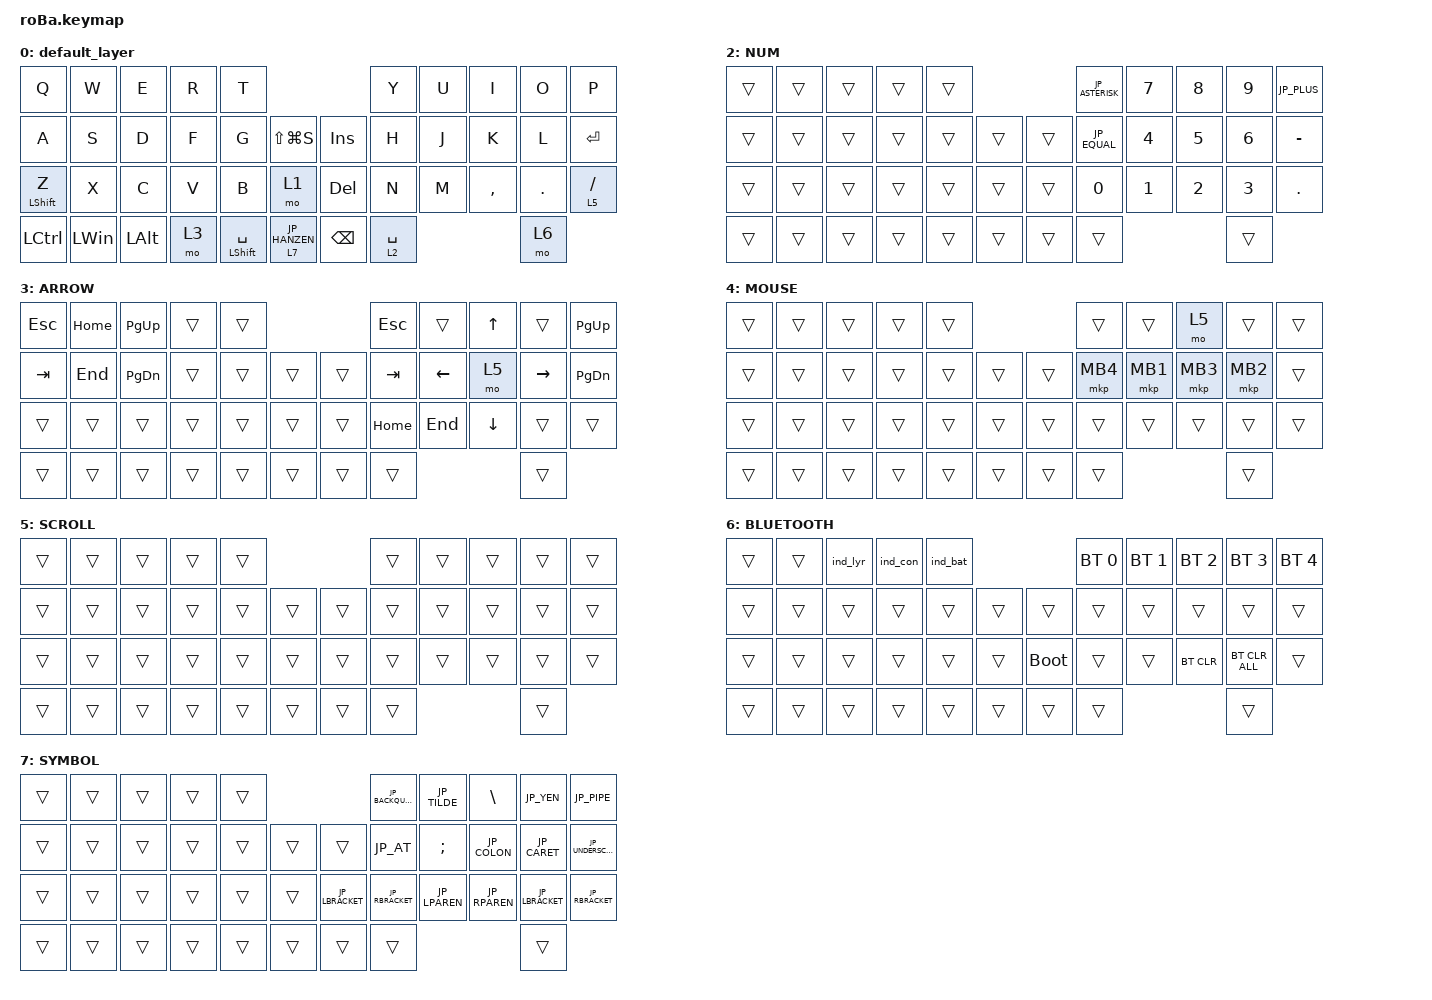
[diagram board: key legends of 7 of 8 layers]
#include <behaviors.dtsi>
#include <dt-bindings/zmk/bt.h>
#include <dt-bindings/zmk/keys.h>
#include <dt-bindings/zmk/pointing.h>
#include <behaviors/rgbled_widget.dtsi>  // led

//エンコーダのスクロール量を定義
#define ZMK_POINTING_DEFAULT_SCRL_VAL 80

// OS設定を日本語キーボードのまま使用するための変換定義
#define JP_DQUOTE       AT                // "
#define JP_AMPERSAND    CARET             // &
#define JP_QUOTE        AMPERSAND         // '
#define JP_EQUAL        UNDER             // =
#define JP_CARET        EQUAL             // ^
#define JP_YEN          0x89              // ¥
#define JP_PLUS         COLON             // +
#define JP_TILDE        PLUS              // ~
#define JP_PIPE         LS(0x89)          // |
#define JP_AT           LEFT_BRACKET      // @
#define JP_COLON        SINGLE_QUOTE      // :
#define JP_ASTERISK     DOUBLE_QUOTES     // *
#define JP_BACKQUOTE    LEFT_BRACE        // `
#define JP_UNDERSCORE   LS(0x87)          // _
#define JP_LBRACKET     RIGHT_BRACKET     // [
#define JP_RBRACKET     BACKSLASH         // ]
#define JP_LPAREN       ASTERISK          // (
#define JP_RPAREN       LEFT_PARENTHESIS  // )
#define JP_LBRACE       RIGHT_BRACE       // {
#define JP_RBRACE       PIPE              // }
#define JP_KANA         LANGUAGE_1        // かな
#define JP_EISU         LANGUAGE_2        // 英数
#define JP_HANZEN       GRAVE             // 半角/全角

&mt {
    flavor = "balanced";
    quick-tap-ms = <0>;
};

&trackball {
    automouse-layer = <4>;
    scroll-layers = <5>;

    // arrows {
    //     layers = <3>;
    //     bindings =
    //         <&kp RIGHT_ARROW>,
    //         <&kp LEFT_ARROW>,
    //         <&kp UP_ARROW>,
    //         <&kp DOWN_ARROW>;
    //     tick = <10>;
    //     wait-ms = <5>;
    //     tap-ms = <5>;
    // };
};

/ {
    combos {
        compatible = "zmk,combos";

        tab {
            bindings = <&kp TAB>;
            key-positions = <11 12>;
        };

        shift_tab {
            bindings = <&kp LS(TAB)>;
            key-positions = <12 13>;
        };

//        muhennkann {
//            bindings = <&to_layer_0 INT_MUHENKAN>;
//            key-positions = <11 10>;
//        };
//
        double_quotation {
            bindings = <&kp MINUS>;
            key-positions = <18 19>;
        };

        eq {
            bindings = <&kp EQUAL>;
            key-positions = <24 25>;
        };
    };

    macros {
        to_layer_0: to_layer_0 {
            compatible = "zmk,behavior-macro-one-param";
            #binding-cells = <1>;
            bindings = <&to 0 &macro_param_1to1 &kp MACRO_PLACEHOLDER>;
            label = "TO_LAYER_0";
        };

    };

    behaviors {
        // スクロール方向を逆にしたい場合は <&msc SCRL_DOWN> と <&msc SCRL_UP> を入れ替えてください
        encoder_msc_down_up: encoder_msc_down_up {
            compatible = "zmk,behavior-sensor-rotate";
            label = "ENCODER_MSC_DOWN_UP";
            #sensor-binding-cells = <0>;
            bindings = <&msc SCRL_DOWN>, <&msc SCRL_UP>;

            tap-ms = <20>;
        };

        lt_to_layer_0: lt_to_layer_0 {
            compatible = "zmk,behavior-hold-tap";
            label = "LAYER_TAP_TO_0";
            bindings = <&mo>, <&to_layer_0>;

            #binding-cells = <2>;
            tapping-term-ms = <200>;
        };

    };

    keymap {
        compatible = "zmk,keymap";

        default_layer {
            bindings = <
&kp Q  &kp W         &kp E         &kp R      &kp T                                                            &kp Y          &kp U  &kp I    &kp O    &kp P
&kp A  &kp S  &kp D  &kp F  &kp G  &kp LS(LG(S))   &kp INS  &kp H  &kp J  &kp K  &kp  L  &kp ENTER
&mt LEFT_SHIFT Z  &kp X         &kp C         &kp V      &kp B                 &mo 1              &kp DEL                 &kp N          &kp M  &kp COMMA  &kp DOT  &lt_to_layer_0 5 SLASH
&kp LCTRL  &kp LEFT_WIN  &kp LEFT_ALT  &mo 3   &mt LEFT_SHIFT SPACE  &lt_to_layer_0 7 JP_HANZEN  &kp BACKSPACE  &lt 2 SPACE  &mo 6  
            >;

            sensor-bindings = <&encoder_msc_down_up>;

            //sensor-bindings = <&inc_dec_kp K_SCROLL_DOWN K_SCROLL_UP>;
        };

        FUNCTION {
            bindings = <
&trans  &trans  &trans  &trans  &trans                      &kp F1  &kp F2  &kp F3  &kp F4  &kp F5
&trans  &trans  &trans  &trans  &trans              &trans  &kp F6  &kp F7  &kp F8  &kp F9   &kp F10
&trans  &trans  &trans  &trans  &trans  &trans      &trans  &trans  &trans  &trans  &kp F11  &kp F12
&trans  &trans  &trans  &trans  &trans  &trans      &trans  &trans                           &trans
            >;
        };

        NUM {
            bindings = <
&trans  &trans  &trans  &trans  &trans                      &kp JP_ASTERISK  &kp N7  &kp N8  &kp N9  &kp JP_PLUS  
&trans  &trans  &trans  &trans  &trans  &trans      &trans  &kp JP_EQUAL     &kp N4  &kp N5  &kp N6  &kp MINUS
&trans  &trans  &trans  &trans  &trans  &trans      &trans  &kp N0           &kp N1  &kp N2  &kp N3  &kp DOT
&trans  &trans  &trans  &trans  &trans  &trans      &trans  &trans                          &trans
            >;
        };

        ARROW {
            bindings = <
&kp ESCAPE  &kp HOME  &kp PAGE_UP    &trans  &trans                      &kp ESCAPE  &trans          &kp UP_ARROW    &trans           &kp PAGE_UP
&kp TAB     &kp END   &kp PAGE_DOWN  &trans  &trans  &trans      &trans  &kp TAB  &kp LEFT_ARROW  &mo  5 &kp RIGHT_ARROW  &kp PAGE_DOWN
&trans      &trans    &trans         &trans  &trans  &trans      &trans  &kp HOME  &kp END          &kp DOWN_ARROW          &trans           &trans
&trans      &trans    &trans         &trans  &trans  &trans      &trans  &trans                                                   &trans
            >;

            sensor-bindings = <&inc_dec_kp LC(PAGE_UP) LC(PAGE_DOWN)>;
        };

        MOUSE {
            bindings = <
&trans  &trans  &trans  &trans  &trans                      &trans  &trans    &mo 5    &trans    &trans
&trans  &trans  &trans  &trans  &trans  &trans      &trans  &mkp MB4  &mkp MB1  &mkp MB3  &mkp MB2  &trans
&trans  &trans  &trans  &trans  &trans  &trans      &trans  &trans  &trans    &trans    &trans    &trans
&trans  &trans  &trans  &trans  &trans  &trans      &trans  &trans                                &trans
            >;
        };

        SCROLL {
            bindings = <
&trans  &trans  &trans  &trans  &trans                      &trans  &trans  &trans  &trans  &trans
&trans  &trans  &trans  &trans  &trans  &trans      &trans  &trans  &trans  &trans  &trans  &trans
&trans  &trans  &trans  &trans  &trans  &trans      &trans  &trans  &trans  &trans  &trans  &trans
&trans  &trans  &trans  &trans  &trans  &trans      &trans  &trans                          &trans
            >;
        };

        BLUETOOTH {
            bindings = <
&trans  &trans  &ind_lyr  &ind_con  &ind_bat                           &bt BT_SEL 0  &bt BT_SEL 1  &bt BT_SEL 2  &bt BT_SEL 3  &bt BT_SEL 4
&trans  &trans  &trans  &trans  &trans  &trans      &trans       &trans        &trans        &trans        &trans        &trans
&trans  &trans  &trans  &trans  &trans  &trans      &bootloader  &trans        &trans        &bt BT_CLR        &bt BT_CLR_ALL        &trans
&trans  &trans  &trans  &trans  &trans  &trans      &trans       &trans                                                  &trans
            >;
            sensor-bindings = 
                <&inc_dec_kp C_VOL_DN C_VOL_UP>;
        };

        SYMBOL {
            bindings = <
&trans  &trans  &trans  &trans  &trans                      &kp JP_BACKQUOTE  &kp JP_TILDE  &kp BACKSLASH  &kp JP_YEN  &kp JP_PIPE
&trans  &trans  &trans  &trans  &trans  &trans      &trans  &kp JP_AT  &kp SEMICOLON  &kp JP_COLON  &kp JP_CARET  &kp JP_UNDERSCORE
&trans  &trans  &trans  &trans  &trans  &trans      &kp JP_LBRACKET  &kp JP_RBRACKET  &kp JP_LPAREN  &kp JP_RPAREN  &kp JP_LBRACKET  &kp JP_RBRACKET
&trans  &trans  &trans  &trans  &trans  &trans      &trans  &trans                          &trans
            >;
        };
    };
};
